# PIC32CZ1038MC70100 register map
Vendor: Microchip Technology; Series: PIC32CZMC70; File version: 0
CPU: CM7 r1p1, little endian, MPU, FPU, double-precision FPU, I-cache, D-cache, ITCM, DTCM, 3 interrupt priority bits, 70 interrupts
Registers are 32-bit, read-write, reset 0x0 unless marked. A register's access mark holds for its fields unless they carry their own. Offsets are from the block's base; [hi:lo] are bit positions; {n}, {i} and the like mark numbered series; 'fields as' and 'values as' point back to an identical list.

## SUPC — Supply Controller
Base 0x400E1810
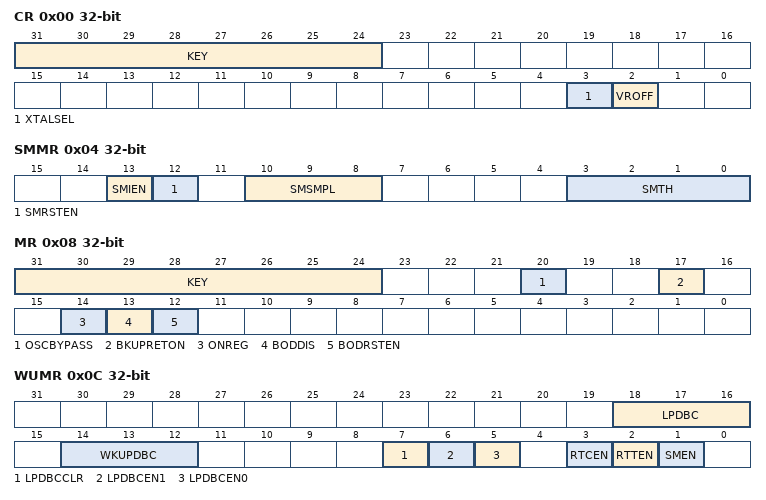
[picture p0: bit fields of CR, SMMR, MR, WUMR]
0x00 CR wo — Supply Controller Control Register
  [31:24] KEY — Password
    165=PASSWD (Writing any other value in this field aborts the write operation.)
  [3] XTALSEL — Crystal Oscillator Select
    0=NO_EFFECT; 1=CRYSTAL_SEL (If KEY is correct, XTALSEL switches the slow clock on the crystal oscillator output.)
  [2] VROFF — Voltage Regulator Off
    0=NO_EFFECT; 1=STOP_VREG (If KEY is correct, VROFF asserts the vddcore_nreset and stops the voltage regulator.)
0x04 SMMR — Supply Controller Supply Monitor Mode Register
  [13] SMIEN — Supply Monitor Interrupt Enable
    0=NOT_ENABLE (The SUPC interrupt signal is not affected when a supply monitor detection occurs.); 1=ENABLE (The SUPC interrupt signal is asserted when a supply monitor detection occurs.)
  [12] SMRSTEN — Supply Monitor Reset Enable
    0=NOT_ENABLE (The core reset signal vddcore_nreset is not affected when a supply monitor detection occurs.); 1=ENABLE (The core reset signal, vddcore_nreset is asserted when a supply monitor detection occurs.)
  [10:8] SMSMPL — Supply Monitor Sampling Period
    0=SMD (Supply Monitor disabled); 1=CSM (Continuous Supply Monitor); 2=_32SLCK (Supply Monitor enabled one SLCK period every 32 SLCK periods); 3=_256SLCK (Supply Monitor enabled one SLCK period every 256 SLCK periods); 4=_2048SLCK (Supply Monitor enabled one SLCK period every 2,048 SLCK periods)
  [3:0] SMTH — Supply Monitor Threshold
0x08 MR — Supply Controller Mode Register
  [31:24] KEY — Password Key
    values as CR.KEY
  [20] OSCBYPASS — Oscillator Bypass
    0=NO_EFFECT (No effect. Clock selection depends on the value of XTALSEL (SUPC_CR).); 1=BYPASS (The 32 kHz crystal oscillator is bypassed if XTALSEL (SUPC_CR) is set. OSCBYPASS must be set prior to setting XTALSEL.)
  [17] BKUPRETON — SRAM On In Backup Mode
  [14] ONREG — Voltage Regulator Enable
    0=ONREG_UNUSED (Internal voltage regulator is not used (external power supply is used).); 1=ONREG_USED (Internal voltage regulator is used.)
  [13] BODDIS — Brownout Detector Disable
    0=ENABLE (The core brownout detector is enabled.); 1=DISABLE (The core brownout detector is disabled.)
  [12] BODRSTEN — Brownout Detector Reset Enable
    0=NOT_ENABLE (The core reset signal vddcore_nreset is not affected when a brownout detection occurs.); 1=ENABLE (The core reset signal, vddcore_nreset is asserted when a brownout detection occurs.)
0x0C WUMR — Supply Controller Wake-up Mode Register
  [18:16] LPDBC — Low-power Debouncer Period
    0=DISABLE (Disable the low-power debouncers.); {v}=_{v+1}_RTCOUT (WKUP0/1 in active state for at least {v+1} RTCOUTx clock periods) (v=1..7)
  [14:12] WKUPDBC — Wake-up Inputs Debouncer Period
    0=IMMEDIATE (Immediate, no debouncing, detected active at least on one Slow Clock edge.); 1=_3_SLCK (WKUPx shall be in its active state for at least 3 SLCK periods); 2=_32_SLCK (WKUPx shall be in its active state for at least 32 SLCK periods); 3=_512_SLCK (WKUPx shall be in its active state for at least 512 SLCK periods); 4=_4096_SLCK (WKUPx shall be in its active state for at least 4,096 SLCK periods); 5=_32768_SLCK (WKUPx shall be in its active state for at least 32,768 SLCK periods)
  [7] LPDBCCLR — Low-power Debouncer Clear
    0=NOT_ENABLE (A low-power debounce event does not create an immediate clear on the first half of GPBR registers.); 1=ENABLE (A low-power debounce event on WKUP0 or WKUP1 generates an immediate clear on the first half of GPBR registers.)
  [6] LPDBCEN1 — Low-power Debouncer Enable WKUP1
    0=NOT_ENABLE (The WKUP1 input pin is not connected to the low-power debouncer.); 1=ENABLE (The WKUP1 input pin is connected to the low-power debouncer and forces a system wake-up.)
  [5] LPDBCEN0 — Low-power Debouncer Enable WKUP0
    0=NOT_ENABLE (The WKUP0 input pin is not connected to the low-power debouncer.); 1=ENABLE (The WKUP0 input pin is connected to the low-power debouncer and forces a system wake-up.)
  [3] RTCEN — Real-time Clock Wake-up Enable
    0=NOT_ENABLE (The RTC alarm signal has no wake-up effect.); 1=ENABLE (The RTC alarm signal forces the wake-up of the core power supply.)
  [2] RTTEN — Real-time Timer Wake-up Enable
    0=NOT_ENABLE (The RTT alarm signal has no wake-up effect.); 1=ENABLE (The RTT alarm signal forces the wake-up of the core power supply.)
  [1] SMEN — Supply Monitor Wake-up Enable
    0=NOT_ENABLE (The supply monitor detection has no wake-up effect.); 1=ENABLE (The supply monitor detection forces the wake-up of the core power supply.)
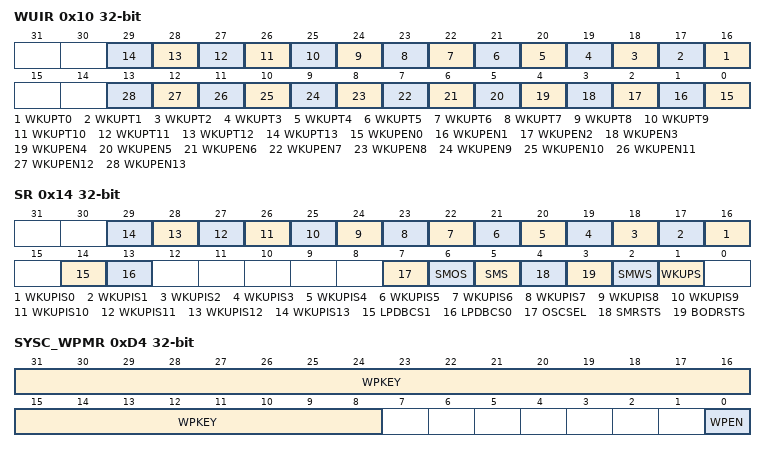
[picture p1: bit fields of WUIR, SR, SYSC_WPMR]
0x10 WUIR — Supply Controller Wake-up Inputs Register
  [n+16] WKUPT{n} (n=0..13) — Wake-up Input Type 0 to {n}
    0=LOW (A falling edge followed by a low level for a period defined by WKUPDBC on the corre-sponding wake-up input forces the wake-up of the core power supply.); 1=HIGH (A rising edge followed by a high level for a period defined by WKUPDBC on the cor-responding wake-up input forces the wake-up of the core power supply.)
  [n] WKUPEN{n} (n=0..13) — Wake-up Input Enable 0 to {n}
    0=DISABLE (The corresponding wake-up input has no wake-up effect.); 1=ENABLE (The corresponding wake-up input is enabled for a wake-up of the core power supply.)
0x14 SR ro — Supply Controller Status Register
  [n+16] WKUPIS{n} (n=0..13) — WKUPx Input Status (cleared on read)
    0=DIS (The corresponding wake-up input is disabled, or was inactive at the time the debouncer triggered a wake-up event.); 1=EN (The corresponding wake-up input was active at the time the debouncer triggered a wake-up event since the last read of SUPC_SR.)
  [14] LPDBCS1 — Low-power Debouncer Wake-up Status on WKUP1 (cleared on read)
    0=NO (No wake-up due to the assertion of the WKUP1 pin has occurred since the last read of SUPC_SR.); 1=PRESENT (At least one wake-up due to the assertion of the WKUP1 pin has occurred since the last read of SUPC_SR.)
  [13] LPDBCS0 — Low-power Debouncer Wake-up Status on WKUP0 (cleared on read)
    0=NO (No wake-up due to the assertion of the WKUP0 pin has occurred since the last read of SUPC_SR.); 1=PRESENT (At least one wake-up due to the assertion of the WKUP0 pin has occurred since the last read of SUPC_SR.)
  [7] OSCSEL — 32-kHz Oscillator Selection Status
    0=RC (The slow clock, SLCK, is generated by the embedded 32 kHz RC oscillator.); 1=CRYST (The slow clock, SLCK, is generated by the 32 kHz crystal oscillator.)
  [6] SMOS — Supply Monitor Output Status
    0=HIGH (The supply monitor detected VDDIO higher than its threshold at its last measurement.); 1=LOW (The supply monitor detected VDDIO lower than its threshold at its last measurement.)
  [5] SMS — Supply Monitor Status (cleared on read)
    0=NO (No supply monitor detection since the last read of SUPC_SR.); 1=PRESENT (At least one supply monitor detection since the last read of SUPC_SR.)
  [4] SMRSTS — Supply Monitor Reset Status (cleared on read)
    0=NO (No supply monitor detection has generated a core reset since the last read of the SUPC_SR.); 1=PRESENT (At least one supply monitor detection has generated a core reset since the last read of the SUPC_SR.)
  [3] BODRSTS — Brownout Detector Reset Status (cleared on read)
    0=NO (No core brownout rising edge event has been detected since the last read of the SUPC_SR.); 1=PRESENT (At least one brownout output rising edge event has been detected since the last read of the SUPC_SR.)
  [2] SMWS — Supply Monitor Detection Wake-up Status (cleared on read)
    0=NO (No wake-up due to a supply monitor detection has occurred since the last read of SUPC_SR.); 1=PRESENT (At least one wake-up due to a supply monitor detection has occurred since the last read of SUPC_SR.)
  [1] WKUPS — WKUP Wake-up Status (cleared on read)
    0=NO (No wake-up due to the assertion of the WKUP pins has occurred since the last read of SUPC_SR.); 1=PRESENT (At least one wake-up due to the assertion of the WKUP pins has occurred since the last read of SUPC_SR.)
0xD4 SYSC_WPMR — Write Protection Mode Register
  [31:8] WPKEY — Write Protection Key
    0x525443=PASSWD (Writing any other value in this field aborts the write operation of the WPEN bit. Always reads as 0.)
  [0] WPEN — Write Protection Enable

## Notices in the file
Copyright (c) 2026 Microchip Technology Inc.
SPDX-License-Identifier: Apache-2.0
Licensed under the Apache License, Version 2.0 (the "License");
you may not use this file except in compliance with the License.
You may obtain a copy of the License at
http://www.apache.org/licenses/LICENSE-2.0
Unless required by applicable law or agreed to in writing, software
distributed under the License is distributed on an "AS IS" BASIS,
WITHOUT WARRANTIES OR CONDITIONS OF ANY KIND, either express or implied.
See the License for the specific language governing permissions and
limitations under the License.
